VERSION ""

NS_ :

BS_:

BU_: InputECU PowertrainECU DashboardECU

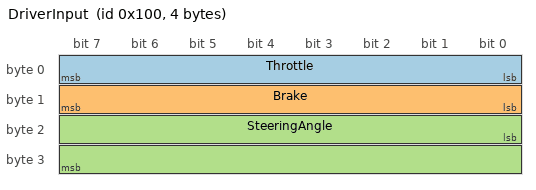
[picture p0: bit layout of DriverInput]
BO_ 256 DriverInput: 4 InputECU
SG_ Throttle : 0|8@1+ (1,0) [0|100] "%" PowertrainECU
SG_ Brake : 8|8@1+ (1,0) [0|100] "%" PowertrainECU
SG_ SteeringAngle : 16|16@1- (0.1,0) [-90|90] "deg" DashboardECU

BO_ 512 PowertrainStatus: 4 PowertrainECU
SG_ Speed : 0|16@1+ (0.1,0) [0|250] "km/h" DashboardECU
SG_ RPM : 16|16@1+ (0.25,0) [0|8000] "rpm" DashboardECU
